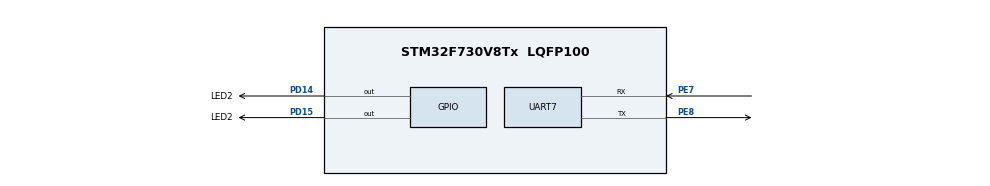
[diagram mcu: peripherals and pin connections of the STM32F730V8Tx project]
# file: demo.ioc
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Mcu.Family=STM32F7
PH0-OSC_IN.Signal=RCC_OSC_IN
FREERTOS.Tasks01=defaultTask,24,128,StartDefaultTask,Default,NULL,Dynamic,NULL,NULL;osTask,32,1024,osTaskEntry,Default,NULL,Dynamic,NULL,NULL
PD15.GPIO_Label=LED2
ProjectManager.StackSize=0x400
VP_FREERTOS_VS_CMSIS_V2.Mode=CMSIS_V2
PE8.Mode=Asynchronous
ProjectManager.TargetToolchain=STM32CubeIDE
RCC.USBFreq_Value=96000000
RCC.LSE_VALUE=32768
PH0-OSC_IN.Mode=HSE-External-Oscillator
RCC.HSE_VALUE=25000000
PD14.PinState=GPIO_PIN_SET
board=custom
RCC.VCOOutputFreq_Value=192000000
PD15.PinState=GPIO_PIN_SET
PE8.Signal=UART7_TX
PH1-OSC_OUT.Signal=RCC_OSC_OUT
PD14.GPIO_Label=LED2
Mcu.Name=STM32F730V8Tx
PD14.Signal=GPIO_Output
PH1-OSC_OUT.Mode=HSE-External-Oscillator
Mcu.Package=LQFP100
PE7.Mode=Asynchronous
ProjectManager.HeapSize=0x200
RCC.HSI_VALUE=16000000
NVIC.PriorityGroup=NVIC_PRIORITYGROUP_4
PE7.Signal=UART7_RX
PD15.Signal=GPIO_Output
NVIC.UART7_IRQn=true\:5\:0\:false\:false\:true\:true\:true\:true

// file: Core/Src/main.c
/* USER CODE BEGIN Header */
/**
  ******************************************************************************
  * @file           : main.c
  * @brief          : Main program body
  ******************************************************************************
  * @attention
  *
  * <h2><center>&copy; Copyright (c) 2023 STMicroelectronics.
  * All rights reserved.</center></h2>
  *
  * This software component is licensed by ST under BSD 3-Clause license,
  * the "License"; You may not use this file except in compliance with the
  * License. You may obtain a copy of the License at:
  *                        opensource.org/licenses/BSD-3-Clause
  *
  ******************************************************************************
  */
/* USER CODE END Header */
#include "main.h"
#include "cmsis_os.h"

/* USER CODE BEGIN Includes */
#include "stdio.h"
/* USER CODE END Includes */

UART_HandleTypeDef huart7;

/* Definitions for defaultTask */
osThreadId_t defaultTaskHandle;
const osThreadAttr_t defaultTask_attributes = {
  .name = "defaultTask",
  .stack_size = 128 * 4,
  .priority = (osPriority_t) osPriorityNormal,
};
/* Definitions for osTask */
osThreadId_t osTaskHandle;
const osThreadAttr_t osTask_attributes = {
  .name = "osTask",
  .stack_size = 1024 * 4,
  .priority = (osPriority_t) osPriorityAboveNormal,
};

void SystemClock_Config(void);
static void MX_GPIO_Init(void);
static void MX_UART7_Init(void);
void StartDefaultTask(void *argument);
void osTaskEntry(void *argument);

/* USER CODE BEGIN PFP */
#ifdef __GNUC__
  #define PUTCHAR_PROTOTYPE int __io_putchar(int ch)
#else
  #define PUTCHAR_PROTOTYPE int fputc(int ch, FILE *f)
#endif
PUTCHAR_PROTOTYPE
{
    HAL_UART_Transmit(&huart7, (uint8_t *)&ch, 1, 0xFF);
    return ch;
}
/* USER CODE END PFP */

int main(void)
{

  /* MCU Configuration--------------------------------------------------------*/

  /* Reset of all peripherals, Initializes the Flash interface and the Systick. */
  HAL_Init();

  /* Configure the system clock */
  SystemClock_Config();

  /* Initialize all configured peripherals */
  MX_GPIO_Init();
  MX_UART7_Init();

  /* Init scheduler */
  osKernelInitialize();

  /* Create the thread(s) */
  /* creation of defaultTask */
  defaultTaskHandle = osThreadNew(StartDefaultTask, NULL, &defaultTask_attributes);

  /* creation of osTask */
  osTaskHandle = osThreadNew(osTaskEntry, NULL, &osTask_attributes);

  /* Start scheduler */
  osKernelStart();

  /* We should never get here as control is now taken by the scheduler */
  /* Infinite loop */
  while (1)
  {

  }
}

void SystemClock_Config(void)
{
  RCC_OscInitTypeDef RCC_OscInitStruct = {0};
  RCC_ClkInitTypeDef RCC_ClkInitStruct = {0};
  RCC_PeriphCLKInitTypeDef PeriphClkInitStruct = {0};

  /** Configure the main internal regulator output voltage
  */
  __HAL_RCC_PWR_CLK_ENABLE();
  __HAL_PWR_VOLTAGESCALING_CONFIG(PWR_REGULATOR_VOLTAGE_SCALE3);
  /** Initializes the RCC Oscillators according to the specified parameters
  * in the RCC_OscInitTypeDef structure.
  */
  RCC_OscInitStruct.OscillatorType = RCC_OSCILLATORTYPE_HSI;
  RCC_OscInitStruct.HSIState = RCC_HSI_ON;
  RCC_OscInitStruct.HSICalibrationValue = RCC_HSICALIBRATION_DEFAULT;
  RCC_OscInitStruct.PLL.PLLState = RCC_PLL_NONE;
  if (HAL_RCC_OscConfig(&RCC_OscInitStruct) != HAL_OK)
  {
    Error_Handler();
  }
  /** Initializes the CPU, AHB and APB buses clocks
  */
  RCC_ClkInitStruct.ClockType = RCC_CLOCKTYPE_HCLK|RCC_CLOCKTYPE_SYSCLK
                              |RCC_CLOCKTYPE_PCLK1|RCC_CLOCKTYPE_PCLK2;
  RCC_ClkInitStruct.SYSCLKSource = RCC_SYSCLKSOURCE_HSI;
  RCC_ClkInitStruct.AHBCLKDivider = RCC_SYSCLK_DIV1;
  RCC_ClkInitStruct.APB1CLKDivider = RCC_HCLK_DIV1;
  RCC_ClkInitStruct.APB2CLKDivider = RCC_HCLK_DIV1;

  if (HAL_RCC_ClockConfig(&RCC_ClkInitStruct, FLASH_LATENCY_0) != HAL_OK)
  {
    Error_Handler();
  }
  PeriphClkInitStruct.PeriphClockSelection = RCC_PERIPHCLK_UART7;
  PeriphClkInitStruct.Uart7ClockSelection = RCC_UART7CLKSOURCE_PCLK1;
  if (HAL_RCCEx_PeriphCLKConfig(&PeriphClkInitStruct) != HAL_OK)
  {
    Error_Handler();
  }
}

static void MX_UART7_Init(void)
{

  huart7.Instance = UART7;
  huart7.Init.BaudRate = 115200;
  huart7.Init.WordLength = UART_WORDLENGTH_8B;
  huart7.Init.StopBits = UART_STOPBITS_1;
  huart7.Init.Parity = UART_PARITY_NONE;
  huart7.Init.Mode = UART_MODE_TX_RX;
  huart7.Init.HwFlowCtl = UART_HWCONTROL_NONE;
  huart7.Init.OverSampling = UART_OVERSAMPLING_16;
  huart7.Init.OneBitSampling = UART_ONE_BIT_SAMPLE_DISABLE;
  huart7.AdvancedInit.AdvFeatureInit = UART_ADVFEATURE_NO_INIT;
  if (HAL_UART_Init(&huart7) != HAL_OK)
  {
    Error_Handler();
  }

}

static void MX_GPIO_Init(void)
{
  GPIO_InitTypeDef GPIO_InitStruct = {0};

  /* GPIO Ports Clock Enable */
  __HAL_RCC_GPIOH_CLK_ENABLE();
  __HAL_RCC_GPIOE_CLK_ENABLE();
  __HAL_RCC_GPIOD_CLK_ENABLE();

  /*Configure GPIO pin Output Level */
  HAL_GPIO_WritePin(GPIOD, LED2_Pin|LED2D15_Pin, GPIO_PIN_SET);

  /*Configure GPIO pins : LED2_Pin LED2D15_Pin */
  GPIO_InitStruct.Pin = LED2_Pin|LED2D15_Pin;
  GPIO_InitStruct.Mode = GPIO_MODE_OUTPUT_PP;
  GPIO_InitStruct.Pull = GPIO_NOPULL;
  GPIO_InitStruct.Speed = GPIO_SPEED_FREQ_LOW;
  HAL_GPIO_Init(GPIOD, &GPIO_InitStruct);

}

void StartDefaultTask(void *argument)
{
  for(;;)
  {
    osDelay(1);
  }
}

void osTaskEntry(void *argument)
{
  /* USER CODE BEGIN osTaskEntry */
  uint32_t os_task_heartbeat = 0;
  /* Infinite loop */
  for(;;)
  {
    if (os_task_heartbeat++ > 1000)
    {
        printf("fighter\r\n");
        os_task_heartbeat = 0;
    }
    osDelay(1);
  }
  /* USER CODE END osTaskEntry */
}

void Error_Handler(void)
{
  __disable_irq();
  while (1)
  {
  }
}

/************************ (C) COPYRIGHT STMicroelectronics *****END OF FILE****/
